# STM32H7x5 register map
File version: 1.1
CPU: CM7 r0p0, little endian, no MPU, no FPU, 3 interrupt priority bits
Registers are 32-bit, read-write, reset 0x0 unless marked. A register's access mark holds for its fields unless they carry their own. Offsets are from the block's base; [hi:lo] are bit positions; {n}, {i} and the like mark numbered series.

## GPIOA — GPIO
Base 0x58020000
Same registers: GPIOB 0x58020400, GPIOC 0x58020800, GPIOD 0x58020C00, GPIOE 0x58021000, GPIOF 0x58021400, GPIOG 0x58021800, GPIOH 0x58021C00, GPIOI 0x58022000, GPIOJ 0x58022400, GPIOK 0x58022800
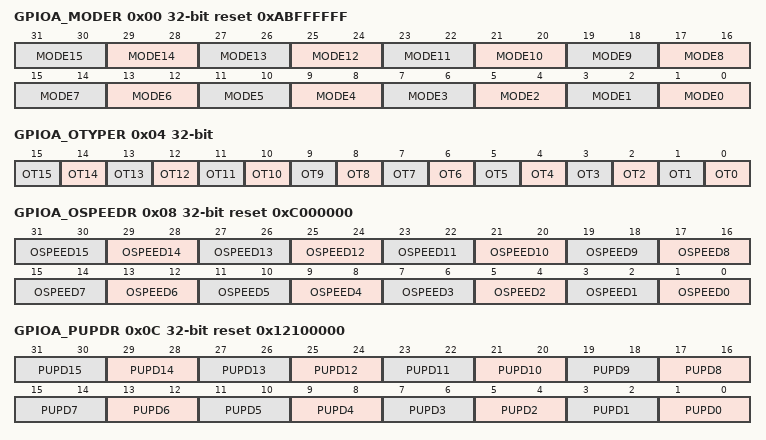
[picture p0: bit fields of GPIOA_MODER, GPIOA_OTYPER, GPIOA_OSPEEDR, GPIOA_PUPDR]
0x00 GPIOA_MODER reset 0xABFFFFFF — GPIO port mode register
  [2n+1:2n] MODE{n} (n=0..15) — [1:0]: Port x configuration bits (y = 0..15) These bits are written by software to configure the I/O mode.
0x04 GPIOA_OTYPER — GPIO port output type register
  [n] OT{n} (n=0..15) — Port x configuration bits (y = 0..15) These bits are written by software to configure the I/O output type.
0x08 GPIOA_OSPEEDR reset 0xC000000 — GPIO port output speed register
  [2n+1:2n] OSPEED{n} (n=0..15) — [1:0]: Port x configuration bits (y = 0..15) These bits are written by software to configure the I/O output speed. Note: Refer to the device datasheet for the frequency specifications and the power supply and load conditions for each speed.
0x0C GPIOA_PUPDR reset 0x12100000 — GPIO port pull-up/pull-down register
  [2n+1:2n] PUPD{n} (n=0..15) — [1:0]: Port x configuration bits (y = 0..15) These bits are written by software to configure the I/O pull-up or pull-down
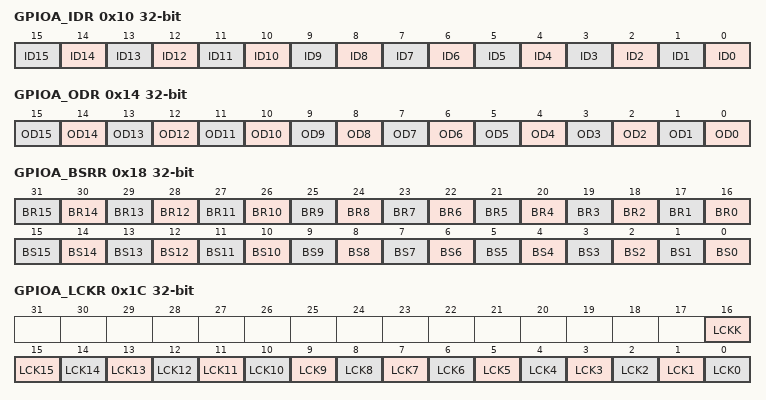
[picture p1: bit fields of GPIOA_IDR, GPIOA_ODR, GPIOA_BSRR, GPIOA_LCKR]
0x10 GPIOA_IDR ro — GPIO port input data register
  [n] ID{n} (n=0..15) — Port input data bit (y = 0..15) These bits are read-only. They contain the input value of the corresponding I/O port.
0x14 GPIOA_ODR — GPIO port output data register
  [n] OD{n} (n=0..15) — Port output data bit These bits can be read and written by software. Note: For atomic bit set/reset, the OD bits can be individually set and/or reset by writing to the GPIOx_BSRR or GPIOx_BRR registers (x = A..F).
0x18 GPIOA_BSRR wo — GPIO port bit set/reset register
  [n+16] BR{n} (n=0..15) — Port x reset bit y (y = 0..15) These bits are write-only. A read to these bits returns the value 0x0000. Note: If both BSx and BRx are set, BSx has priority.
  [n] BS{n} (n=0..15) — Port x set bit y (y= 0..15) These bits are write-only. A read to these bits returns the value 0x0000.
0x1C GPIOA_LCKR — This register is used to lock the configuration of the port bits when a correct write sequence is applied to bit 16 (LCKK). The value of bits [15:0] is used to lock the configuration of the GPIO. During the write sequence, the value of LCKR[15:0] must not change. When the LOCK sequence has been applied on a port bit, the value of this port bit can no longer be modified until the next MCU reset or peripheral reset.A specific write sequence is used to write to the GPIOx_LCKR register. Only word access (32-bit long) is allowed during this locking sequence.Each lock bit freezes a specific configuration register (control and alternate function registers).
  [16] LCKK — Lock key This bit can be read any time. It can only be modified using the lock key write sequence. LOCK key write sequence: WR LCKR[16] = 1 + LCKR[15:0] WR LCKR[16] = 0 + LCKR[15:0] WR LCKR[16] = 1 + LCKR[15:0] RD LCKR RD LCKR[16] = 1 (this read operation is optional but it confirms that the lock is active) Note: During the LOCK key write sequence, the value of LCK[15:0] must not change. Any error in the lock sequence aborts the lock. After the first lock sequence on any bit of the port, any read access on the LCKK bit will return 1 until the next MCU reset or peripheral reset.
  [n] LCK{n} (n=0..15) — Port x lock bit y (y= 0..15) These bits are read/write but can only be written when the LCKK bit is 0.
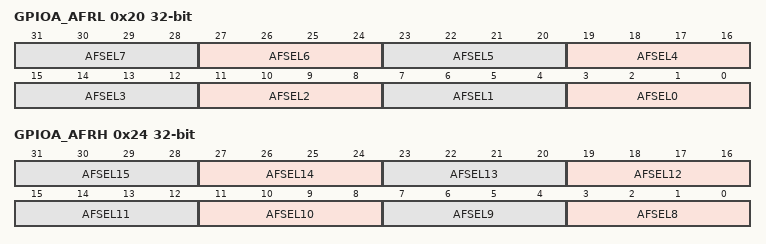
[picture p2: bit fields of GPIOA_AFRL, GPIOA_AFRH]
0x20 GPIOA_AFRL — GPIO alternate function low register
  [4n+3:4n] AFSEL{n} (n=0..7) — [3:0]: Alternate function selection for port x pin y (y = 0..7) These bits are written by software to configure alternate function I/Os AFSELy selection:
0x24 GPIOA_AFRH — GPIO alternate function high register
  [4n-29:4n-32] AFSEL{n} (n=8..15) — [3:0]: Alternate function selection for port x pin y (y = 8..15) These bits are written by software to configure alternate function I/Os
